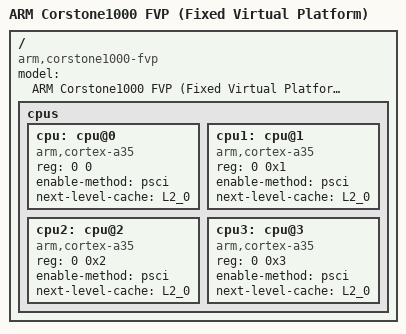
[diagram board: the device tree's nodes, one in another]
// SPDX-License-Identifier: GPL-2.0 OR MIT
/*
 * Copyright (c) 2022, Arm Limited. All rights reserved.
 * Copyright (c) 2022, Linaro Limited. All rights reserved.
 *
 */

/dts-v1/;

#include "corstone1000.dtsi"
#include "corstone1000-fvp.dtsi"

/ {
	model = "ARM Corstone1000 FVP (Fixed Virtual Platform)";
	compatible = "arm,corstone1000-fvp";

	cpus: cpus {
		#address-cells = <2>;
		#size-cells = <0>;

		cpu: cpu@0 {
			device_type = "cpu";
			compatible = "arm,cortex-a35";
			reg = <0 0>;
			enable-method = "psci";
			next-level-cache = <&L2_0>;
		};

		cpu1: cpu@1 {
			device_type = "cpu";
			compatible = "arm,cortex-a35";
			reg = <0 0x1>;
			enable-method = "psci";
			next-level-cache = <&L2_0>;
		};

		cpu2: cpu@2 {
			device_type = "cpu";
			compatible = "arm,cortex-a35";
			reg = <0 0x2>;
			enable-method = "psci";
			next-level-cache = <&L2_0>;
		};

		cpu3: cpu@3 {
			device_type = "cpu";
			compatible = "arm,cortex-a35";
			reg = <0 0x3>;
			enable-method = "psci";
			next-level-cache = <&L2_0>;
		};
	};
};
